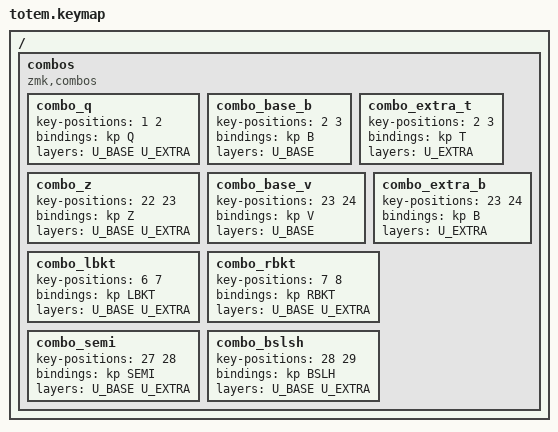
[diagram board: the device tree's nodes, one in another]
// Copyright 2022 Manna Harbour
// https://github.com/manna-harbour/miryoku

#include "../miryoku/custom_config.h"
#include "../miryoku/mapping/38/totem.h"
#include "../miryoku/miryoku.dtsi"

/ {
  combos {
    compatible = "zmk,combos";

    combo_q {
      key-positions = <1 2>;
      bindings = <&kp Q>;
      layers = <U_BASE U_EXTRA>;
    };

    combo_base_b {
      key-positions = <2 3>;
      bindings = <&kp B>;
      layers = <U_BASE>;
    };

    combo_extra_t {
      key-positions = <2 3>;
      bindings = <&kp T>;
      layers = <U_EXTRA>;
    };

    combo_z {
      key-positions = <22 23>;
      bindings = <&kp Z>;
      layers = <U_BASE U_EXTRA>;
    };

    combo_base_v {
      key-positions = <23 24>;
      bindings = <&kp V>;
      layers = <U_BASE>;
    };

    combo_extra_b {
      key-positions = <23 24>;
      bindings = <&kp B>;
      layers = <U_EXTRA>;
    };

    combo_lbkt {
      key-positions = <6 7>;
      bindings = <&kp LBKT>;
      layers = <U_BASE U_EXTRA>;
    };

    combo_rbkt {
      key-positions = <7 8>;
      bindings = <&kp RBKT>;
      layers = <U_BASE U_EXTRA>;
    };

    combo_semi {
      key-positions = <27 28>;
      bindings = <&kp SEMI>;
      layers = <U_BASE U_EXTRA>;
    };

    combo_bslsh {
      key-positions = <28 29>;
      bindings = <&kp BSLH>;
      layers = <U_BASE U_EXTRA>;
    };
  };
};
